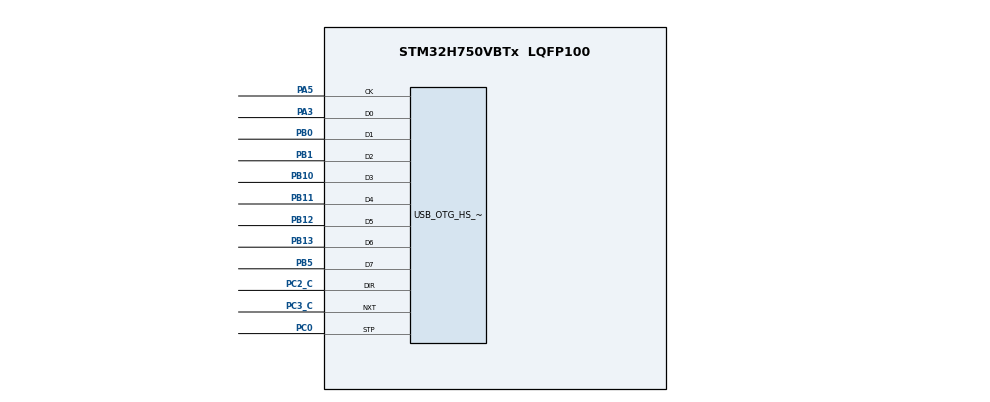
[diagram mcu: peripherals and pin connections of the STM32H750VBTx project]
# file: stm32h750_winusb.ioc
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CORTEX_M7.default_mode_Activation=1
Mcu.Family=STM32H7
Mcu.Name=STM32H750VBTx
Mcu.Package=LQFP100
NVIC.OTG_HS_EP1_IN_IRQn=true\:0\:0\:false\:false\:true\:true\:true\:true
NVIC.OTG_HS_EP1_OUT_IRQn=true\:0\:0\:false\:false\:true\:true\:true\:true
NVIC.OTG_HS_IRQn=true\:0\:0\:false\:false\:true\:true\:true\:true
NVIC.PriorityGroup=NVIC_PRIORITYGROUP_4
PA13\ (JTMS/SWDIO).Mode=Serial_Wire
PA13\ (JTMS/SWDIO).Signal=DEBUG_JTMS-SWDIO
PA14\ (JTCK/SWCLK).Mode=Serial_Wire
PA14\ (JTCK/SWCLK).Signal=DEBUG_JTCK-SWCLK
PA3.Mode=Device_HS
PA3.Signal=USB_OTG_HS_ULPI_D0
PA5.Mode=Device_HS
PA5.Signal=USB_OTG_HS_ULPI_CK
PB0.Mode=Device_HS
PB0.Signal=USB_OTG_HS_ULPI_D1
PB1.Mode=Device_HS
PB1.Signal=USB_OTG_HS_ULPI_D2
PB10.Mode=Device_HS
PB10.Signal=USB_OTG_HS_ULPI_D3
PB11.Mode=Device_HS
PB11.Signal=USB_OTG_HS_ULPI_D4
PB12.Mode=Device_HS
PB12.Signal=USB_OTG_HS_ULPI_D5
PB13.Mode=Device_HS
PB13.Signal=USB_OTG_HS_ULPI_D6
PB5.Mode=Device_HS
PB5.Signal=USB_OTG_HS_ULPI_D7
PC0.Mode=Device_HS
PC0.Signal=USB_OTG_HS_ULPI_STP
PC2_C.Mode=Device_HS
PC2_C.Signal=USB_OTG_HS_ULPI_DIR
PC3_C.Mode=Device_HS
PC3_C.Signal=USB_OTG_HS_ULPI_NXT
ProjectManager.HeapSize=0x800
ProjectManager.StackSize=0x1000
ProjectManager.TargetToolchain=CMake
RCC.ADCFreq_Value=129000000
RCC.APB1Freq_Value=120000000
RCC.APB2Freq_Value=120000000
RCC.APB3Freq_Value=120000000
RCC.APB4Freq_Value=120000000
RCC.CortexFreq_Value=480000000
RCC.D1PPRE=RCC_APB3_DIV2
RCC.D2PPRE1=RCC_APB1_DIV2
RCC.D2PPRE2=RCC_APB2_DIV2
RCC.D3PPRE=RCC_APB4_DIV2
RCC.DIVM1=4
RCC.DIVN1=60
RCC.HCLKFreq_Value=240000000
RCC.HPRE=RCC_HCLK_DIV2
RCC.PLL2FRACN=0
RCC.PLL3FRACN=0
RCC.PLLFRACN=0
RCC.SYSCLKFreq_VALUE=480000000
RCC.SYSCLKSource=RCC_SYSCLKSOURCE_PLLCLK
RCC.USBCLockSelection=RCC_USBCLKSOURCE_HSI48
RCC.USBFreq_Value=48000000
USB_DEVICE.CLASS_NAME_HS=CDC
USB_DEVICE.USBD_LPM_ENABLED-CDC_HS=0
USB_DEVICE.VirtualMode-CDC_HS=Cdc
USB_DEVICE.VirtualModeHS=Cdc_HS
USB_OTG_HS.VirtualMode-Device_HS=Device_HS
VP_MEMORYMAP_VS_MEMORYMAP.Mode=CurAppReg
VP_USB_DEVICE_VS_USB_DEVICE_CDC_HS.Mode=CDC_HS
board=custom

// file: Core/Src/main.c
/* USER CODE BEGIN Header */
/**
  ******************************************************************************
  * @file           : main.c
  * @brief          : Main program body
  ******************************************************************************
  * @attention
  *
  * Copyright (c) 2025 STMicroelectronics.
  * All rights reserved.
  *
  * This software is licensed under terms that can be found in the LICENSE file
  * in the root directory of this software component.
  * If no LICENSE file comes with this software, it is provided AS-IS.
  *
  ******************************************************************************
  */
/* USER CODE END Header */
#include "main.h"
#include "usb_device.h"

/* USER CODE BEGIN Includes */
//---------------ADD GUOXUAN--------------------------
#include "usbd_cdc_if.h"

#define DATA_SIZE 40960  // 恢复到原始工作值

uint8_t myData[DATA_SIZE];
//----------------------------------------------------

/* USER CODE END Includes */

/* USER CODE BEGIN PTD */
//--------------ADD GUOXUAN-----------------------

extern USBD_HandleTypeDef hUsbDeviceHS;
//-----------------------------------------------

/* USER CODE END PTD */

void SystemClock_Config(void);
static void MPU_Config(void);
static void MX_GPIO_Init(void);

/* USER CODE BEGIN 0 */
//------------ADD GUOXUAN-------------------
void WinUSB_Receive_HS(uint8_t* data, size_t length)
{

  CDC_Transmit_HS(data, length);
}
//------------------------------------------

/* USER CODE END 0 */

int main(void)
{

  /* MPU Configuration--------------------------------------------------------*/
  MPU_Config();

  /* MCU Configuration--------------------------------------------------------*/

  /* Reset of all peripherals, Initializes the Flash interface and the Systick. */
  HAL_Init();

  /* Configure the system clock */
  SystemClock_Config();

  /* Initialize all configured peripherals */
  MX_GPIO_Init();
  MX_USB_DEVICE_Init();

  /* Infinite loop */
  /* USER CODE BEGIN WHILE */

  for (uint16_t i = 0; i < DATA_SIZE; i++) {
      myData[i] = (i % 2) + 1;  // 使用取模运算填充 1, 2
  }

  while (1)
  {
    CDC_Transmit_HS(myData, DATA_SIZE);

  }

}

void SystemClock_Config(void)
{
  RCC_OscInitTypeDef RCC_OscInitStruct = {0};
  RCC_ClkInitTypeDef RCC_ClkInitStruct = {0};

  /** Supply configuration update enable
  */
  HAL_PWREx_ConfigSupply(PWR_LDO_SUPPLY);

  /** Configure the main internal regulator output voltage
  */
  __HAL_PWR_VOLTAGESCALING_CONFIG(PWR_REGULATOR_VOLTAGE_SCALE0);

  while(!__HAL_PWR_GET_FLAG(PWR_FLAG_VOSRDY)) {}

  /** Initializes the RCC Oscillators according to the specified parameters
  * in the RCC_OscInitTypeDef structure.
  */
  RCC_OscInitStruct.OscillatorType = RCC_OSCILLATORTYPE_HSI48|RCC_OSCILLATORTYPE_HSI;
  RCC_OscInitStruct.HSIState = RCC_HSI_DIV1;
  RCC_OscInitStruct.HSICalibrationValue = RCC_HSICALIBRATION_DEFAULT;
  RCC_OscInitStruct.HSI48State = RCC_HSI48_ON;
  RCC_OscInitStruct.PLL.PLLState = RCC_PLL_ON;
  RCC_OscInitStruct.PLL.PLLSource = RCC_PLLSOURCE_HSI;
  RCC_OscInitStruct.PLL.PLLM = 4;
  RCC_OscInitStruct.PLL.PLLN = 60;
  RCC_OscInitStruct.PLL.PLLP = 2;
  RCC_OscInitStruct.PLL.PLLQ = 2;
  RCC_OscInitStruct.PLL.PLLR = 2;
  RCC_OscInitStruct.PLL.PLLRGE = RCC_PLL1VCIRANGE_3;
  RCC_OscInitStruct.PLL.PLLVCOSEL = RCC_PLL1VCOWIDE;
  RCC_OscInitStruct.PLL.PLLFRACN = 0;
  if (HAL_RCC_OscConfig(&RCC_OscInitStruct) != HAL_OK)
  {
    Error_Handler();
  }

  /** Initializes the CPU, AHB and APB buses clocks
  */
  RCC_ClkInitStruct.ClockType = RCC_CLOCKTYPE_HCLK|RCC_CLOCKTYPE_SYSCLK
                              |RCC_CLOCKTYPE_PCLK1|RCC_CLOCKTYPE_PCLK2
                              |RCC_CLOCKTYPE_D3PCLK1|RCC_CLOCKTYPE_D1PCLK1;
  RCC_ClkInitStruct.SYSCLKSource = RCC_SYSCLKSOURCE_PLLCLK;
  RCC_ClkInitStruct.SYSCLKDivider = RCC_SYSCLK_DIV1;
  RCC_ClkInitStruct.AHBCLKDivider = RCC_HCLK_DIV2;
  RCC_ClkInitStruct.APB3CLKDivider = RCC_APB3_DIV2;
  RCC_ClkInitStruct.APB1CLKDivider = RCC_APB1_DIV2;
  RCC_ClkInitStruct.APB2CLKDivider = RCC_APB2_DIV2;
  RCC_ClkInitStruct.APB4CLKDivider = RCC_APB4_DIV2;

  if (HAL_RCC_ClockConfig(&RCC_ClkInitStruct, FLASH_LATENCY_4) != HAL_OK)
  {
    Error_Handler();
  }
}

static void MX_GPIO_Init(void)
{

  /* GPIO Ports Clock Enable */
  __HAL_RCC_GPIOC_CLK_ENABLE();
  __HAL_RCC_GPIOA_CLK_ENABLE();
  __HAL_RCC_GPIOB_CLK_ENABLE();

}

 /* MPU Configuration */

void MPU_Config(void)
{
  MPU_Region_InitTypeDef MPU_InitStruct = {0};

  /* Disables the MPU */
  HAL_MPU_Disable();

  /** Initializes and configures the Region and the memory to be protected
  */
  MPU_InitStruct.Enable = MPU_REGION_ENABLE;
  MPU_InitStruct.Number = MPU_REGION_NUMBER0;
  MPU_InitStruct.BaseAddress = 0x0;
  MPU_InitStruct.Size = MPU_REGION_SIZE_4GB;
  MPU_InitStruct.SubRegionDisable = 0x87;
  MPU_InitStruct.TypeExtField = MPU_TEX_LEVEL0;
  MPU_InitStruct.AccessPermission = MPU_REGION_NO_ACCESS;
  MPU_InitStruct.DisableExec = MPU_INSTRUCTION_ACCESS_DISABLE;
  MPU_InitStruct.IsShareable = MPU_ACCESS_SHAREABLE;
  MPU_InitStruct.IsCacheable = MPU_ACCESS_NOT_CACHEABLE;
  MPU_InitStruct.IsBufferable = MPU_ACCESS_NOT_BUFFERABLE;

  HAL_MPU_ConfigRegion(&MPU_InitStruct);
  /* Enables the MPU */
  HAL_MPU_Enable(MPU_PRIVILEGED_DEFAULT);

}

void Error_Handler(void)
{
  __disable_irq();
  while (1)
  {
  }
}
